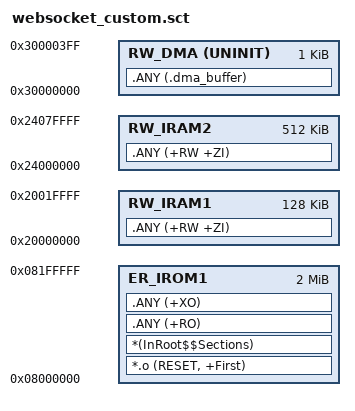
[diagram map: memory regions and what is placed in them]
; STM32H743VIT6 explicit scatter file.
; UART DMA buffers live in D2 SRAM because DMA1 cannot access DTCM.
LR_IROM1 0x08000000 0x00200000  {
  ER_IROM1 0x08000000 0x00200000  {
   *.o (RESET, +First)
   *(InRoot$$Sections)
   .ANY (+RO)
   .ANY (+XO)
  }
  RW_DMA 0x30000000 UNINIT 0x00000400  {
   .ANY (.dma_buffer)
  }
  RW_IRAM1 0x20000000 0x00020000  {
   .ANY (+RW +ZI)
  }
  RW_IRAM2 0x24000000 0x00080000  {
   .ANY (+RW +ZI)
  }
}
